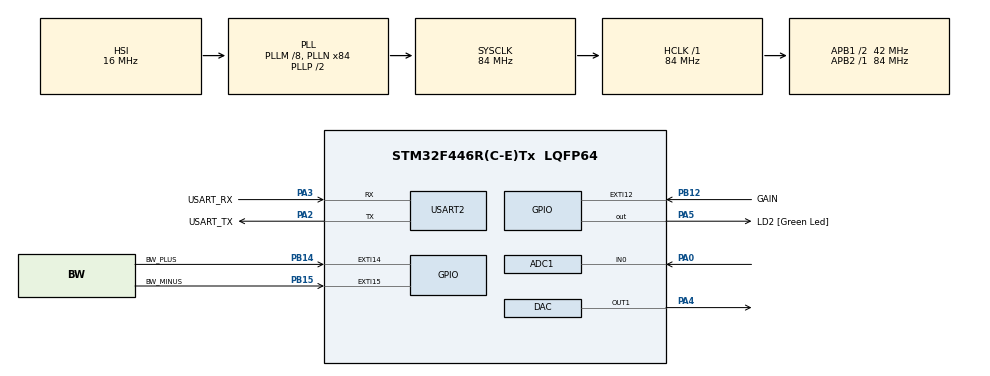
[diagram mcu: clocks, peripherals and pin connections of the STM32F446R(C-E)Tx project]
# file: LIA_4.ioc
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ADC1.Channel-0\#ChannelRegularConversion=ADC_CHANNEL_0
ADC1.ContinuousConvMode=DISABLE
ADC1.DMAContinuousRequests=ENABLE
ADC1.ExternalTrigConv=ADC_EXTERNALTRIGCONV_T2_TRGO
ADC1.NbrOfConversionFlag=1
ADC1.Rank-0\#ChannelRegularConversion=1
ADC1.SamplingTime-0\#ChannelRegularConversion=ADC_SAMPLETIME_28CYCLES
ADC1.ScanConvMode=DISABLE
ADC1.master=1
DAC.DAC_Trigger=DAC_TRIGGER_T2_TRGO
Dma.ADC1.1.Direction=DMA_PERIPH_TO_MEMORY
Dma.ADC1.1.FIFOMode=DMA_FIFOMODE_DISABLE
Dma.ADC1.1.Instance=DMA2_Stream0
Dma.ADC1.1.MemDataAlignment=DMA_MDATAALIGN_HALFWORD
Dma.ADC1.1.MemInc=DMA_MINC_ENABLE
Dma.ADC1.1.Mode=DMA_CIRCULAR
Dma.ADC1.1.PeriphDataAlignment=DMA_PDATAALIGN_HALFWORD
Dma.ADC1.1.PeriphInc=DMA_PINC_DISABLE
Dma.ADC1.1.Priority=DMA_PRIORITY_HIGH
Dma.DAC1.0.Direction=DMA_MEMORY_TO_PERIPH
Dma.DAC1.0.FIFOMode=DMA_FIFOMODE_DISABLE
Dma.DAC1.0.Instance=DMA1_Stream5
Dma.DAC1.0.MemDataAlignment=DMA_MDATAALIGN_HALFWORD
Dma.DAC1.0.MemInc=DMA_MINC_ENABLE
Dma.DAC1.0.Mode=DMA_CIRCULAR
Dma.DAC1.0.PeriphDataAlignment=DMA_PDATAALIGN_HALFWORD
Dma.DAC1.0.PeriphInc=DMA_PINC_DISABLE
Dma.DAC1.0.Priority=DMA_PRIORITY_MEDIUM
Dma.Request0=DAC1
Dma.Request1=ADC1
Mcu.Family=STM32F4
Mcu.Name=STM32F446R(C-E)Tx
Mcu.Package=LQFP64
NVIC.DMA1_Stream5_IRQn=true\:0\:0\:false\:false\:true\:false\:true\:true
NVIC.DMA2_Stream0_IRQn=true\:0\:0\:false\:false\:true\:false\:true\:true
NVIC.EXTI15_10_IRQn=true\:0\:0\:false\:false\:true\:true\:true\:true
NVIC.PriorityGroup=NVIC_PRIORITYGROUP_0
PA0-WKUP.Signal=ADCx_IN0
PA13.GPIO_Label=TMS
PA13.Mode=Serial_Wire
PA13.Signal=SYS_JTMS-SWDIO
PA14.GPIO_Label=TCK
PA14.Mode=Serial_Wire
PA14.Signal=SYS_JTCK-SWCLK
PA2.GPIO_Label=USART_TX
PA2.Mode=Asynchronous
PA2.Signal=USART2_TX
PA3.GPIO_Label=USART_RX
PA3.Mode=Asynchronous
PA3.Signal=USART2_RX
PA4.Signal=COMP_DAC1_group
PA5.GPIO_Label=LD2 [Green Led]
PA5.GPIO_PuPd=GPIO_NOPULL
PA5.Signal=GPIO_Output
PB12.GPIO_Label=GAIN
PB12.GPIO_ModeDefaultEXTI=GPIO_MODE_IT_RISING_FALLING
PB12.GPIO_PuPd=GPIO_PULLUP
PB12.Signal=GPXTI12
PB14.GPIO_Label=BW_PLUS
PB14.GPIO_ModeDefaultEXTI=GPIO_MODE_IT_RISING_FALLING
PB14.GPIO_PuPd=GPIO_PULLUP
PB14.Signal=GPXTI14
PB15.GPIO_Label=BW_MINUS
PB15.GPIO_ModeDefaultEXTI=GPIO_MODE_IT_RISING_FALLING
PB15.GPIO_PuPd=GPIO_PULLUP
PB15.Signal=GPXTI15
PB3.GPIO_Label=SWO
PB3.Signal=SYS_JTDO-SWO
PC14-OSC32_IN.Mode=LSE-External-Oscillator
PC14-OSC32_IN.Signal=RCC_OSC32_IN
PC15-OSC32_OUT.Mode=LSE-External-Oscillator
PC15-OSC32_OUT.Signal=RCC_OSC32_OUT
PH0-OSC_IN.Mode=HSE-External-Oscillator
PH0-OSC_IN.Signal=RCC_OSC_IN
PH1-OSC_OUT.Mode=HSE-External-Oscillator
PH1-OSC_OUT.Signal=RCC_OSC_OUT
ProjectManager.HeapSize=0x200
ProjectManager.StackSize=0x400
ProjectManager.TargetToolchain=STM32CubeIDE
RCC.48MHZClocksFreq_Value=84000000
RCC.AHBFreq_Value=84000000
RCC.APB1CLKDivider=RCC_HCLK_DIV2
RCC.APB1Freq_Value=42000000
RCC.APB1TimFreq_Value=84000000
RCC.APB2Freq_Value=84000000
RCC.APB2TimFreq_Value=84000000
RCC.CortexFreq_Value=84000000
RCC.FLatency-AdvancedSettings=FLASH_LATENCY_2
RCC.HCLKFreq_Value=84000000
RCC.HSE_VALUE=8000000
RCC.HSI_VALUE=16000000
RCC.PLLM=8
RCC.PLLN=84
RCC.SYSCLKFreq_VALUE=84000000
RCC.SYSCLKSource=RCC_SYSCLKSOURCE_PLLCLK
RCC.USBFreq_Value=84000000
RCC.VCOOutputFreq_Value=168000000
SH.ADCx_IN0.0=ADC1_IN0,IN0
SH.COMP_DAC1_group.0=DAC_OUT1,DAC_OUT1
TIM2.Period=209
TIM2.TIM_MasterOutputTrigger=TIM_TRGO_UPDATE
USART2.VirtualMode=VM_ASYNC
VP_TIM2_VS_ClockSourceINT.Mode=Internal
board=NUCLEO-F446RE

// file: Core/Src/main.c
/* USER CODE BEGIN Header */
/**
  ******************************************************************************
  * @file           : main.c
  * @brief          : Main program body
  ******************************************************************************
  * @attention
  *
  * Copyright (c) 2025 STMicroelectronics.
  * All rights reserved.
  *
  * This software is licensed under terms that can be found in the LICENSE file
  * in the root directory of this software component.
  * If no LICENSE file comes with this software, it is provided AS-IS.
  *
  ******************************************************************************
  */
/* USER CODE END Header */
#include "main.h"
#include "adc.h"
#include "dac.h"
#include "dma.h"
#include "tim.h"
#include "usart.h"
#include "gpio.h"

/* USER CODE BEGIN Includes */
#include "lia_core.h"
#include "serial_if.h"

/* USER CODE END Includes */

void SystemClock_Config(void);

int main(void)
{

  /* MCU Configuration--------------------------------------------------------*/

  /* Reset of all peripherals, Initializes the Flash interface and the Systick. */
  HAL_Init();

  /* Configure the system clock */
  SystemClock_Config();

  /* Initialize all configured peripherals */
  MX_GPIO_Init();
  MX_DMA_Init();
  MX_USART2_UART_Init();
  MX_ADC1_Init();
  MX_DAC_Init();
  MX_TIM2_Init();
  /* USER CODE BEGIN 2 */
  NCO_LUT_Generate();
  Serial_Print("Digital LIA on STM32F446RE\r\n");
  Serial_Print("Enter reference frequency (10 Hz ~ 100 kHz):\r\n");

  LIA_SystemInit();
  /* USER CODE END 2 */

  /* Infinite loop */
  /* USER CODE BEGIN WHILE */
  while (1)
  {
	  LIA_Task();

    /* USER CODE END WHILE */

  }
}

void SystemClock_Config(void)
{
  RCC_OscInitTypeDef RCC_OscInitStruct = {0};
  RCC_ClkInitTypeDef RCC_ClkInitStruct = {0};

  /** Configure the main internal regulator output voltage
  */
  __HAL_RCC_PWR_CLK_ENABLE();
  __HAL_PWR_VOLTAGESCALING_CONFIG(PWR_REGULATOR_VOLTAGE_SCALE3);

  /** Initializes the RCC Oscillators according to the specified parameters
  * in the RCC_OscInitTypeDef structure.
  */
  RCC_OscInitStruct.OscillatorType = RCC_OSCILLATORTYPE_HSI;
  RCC_OscInitStruct.HSIState = RCC_HSI_ON;
  RCC_OscInitStruct.HSICalibrationValue = RCC_HSICALIBRATION_DEFAULT;
  RCC_OscInitStruct.PLL.PLLState = RCC_PLL_ON;
  RCC_OscInitStruct.PLL.PLLSource = RCC_PLLSOURCE_HSI;
  RCC_OscInitStruct.PLL.PLLM = 8;
  RCC_OscInitStruct.PLL.PLLN = 84;
  RCC_OscInitStruct.PLL.PLLP = RCC_PLLP_DIV2;
  RCC_OscInitStruct.PLL.PLLQ = 2;
  RCC_OscInitStruct.PLL.PLLR = 2;
  if (HAL_RCC_OscConfig(&RCC_OscInitStruct) != HAL_OK)
  {
    Error_Handler();
  }

  /** Initializes the CPU, AHB and APB buses clocks
  */
  RCC_ClkInitStruct.ClockType = RCC_CLOCKTYPE_HCLK|RCC_CLOCKTYPE_SYSCLK
                              |RCC_CLOCKTYPE_PCLK1|RCC_CLOCKTYPE_PCLK2;
  RCC_ClkInitStruct.SYSCLKSource = RCC_SYSCLKSOURCE_PLLCLK;
  RCC_ClkInitStruct.AHBCLKDivider = RCC_SYSCLK_DIV1;
  RCC_ClkInitStruct.APB1CLKDivider = RCC_HCLK_DIV2;
  RCC_ClkInitStruct.APB2CLKDivider = RCC_HCLK_DIV1;

  if (HAL_RCC_ClockConfig(&RCC_ClkInitStruct, FLASH_LATENCY_2) != HAL_OK)
  {
    Error_Handler();
  }
}

void Error_Handler(void)
{
  __disable_irq();
  while (1)
  {
  }
}
